# MSS_DTHE register map
Vendor: Texas Instruments
Peripheral module from a debugger description file (folder radar).
Registers are 32-bit, access per field, no defined reset value unless marked. A register's access mark holds for its fields unless they carry their own. Offsets are as the file gives them; lines under a group give offsets from that group; [hi:lo] are bit positions; {n}, {i} and the like mark numbered series; 'fields as' and 'values as' point back to an identical list; <NAME> marks a mode.

## MSS_DTHE
0x00 S_EIP_CONFIG rw
  [31:0] CONFIG — This register is secured request configuration.Writing 3 to this register enables the mreqsecure to enable the write to S_SYSCONFIG register in AES and SHA.
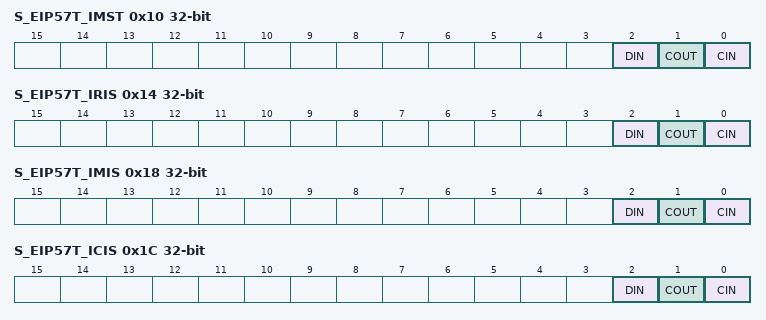
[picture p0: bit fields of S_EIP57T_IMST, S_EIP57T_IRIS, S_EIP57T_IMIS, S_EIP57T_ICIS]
0x10 S_EIP57T_IMST
  [2] DIN rw — Data in: this interrupt is raised when DMA writes last word of input data to internal FIFO of the engine
  [1] COUT rw — Context out: this interrupt is raised when DMA complets the output context movement from internal register
  [0] CIN rw — context in: this interrupt is raised when DMA complets Context write to internal register
0x14 S_EIP57T_IRIS ro
  [2] DIN — input Data movement is done
  [1] COUT — Context output is done
  [0] CIN — context input is done
0x18 S_EIP57T_IMIS ro
  fields as S_EIP57T_IRIS
0x1C S_EIP57T_ICIS
  [2] DIN rw — Clear “input Data movement done” flag
  [1] COUT rw — Clear “Context output done” flag
  [0] CIN rw — Clear “context input done” flag
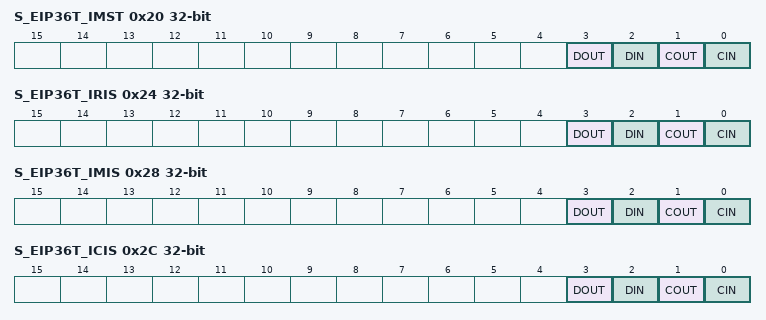
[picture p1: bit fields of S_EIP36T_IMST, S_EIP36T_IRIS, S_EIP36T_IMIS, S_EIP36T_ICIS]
0x20 S_EIP36T_IMST
  [3] DOUT rw — Data out: this interrupt is raised when DMA finishes writing last word of the process result
  [2] DIN rw — Data in: this interrupt is raised when DMA writes last word of input data to internal FIFO of the engine
  [1] COUT rw — Context out: this interrupt is raised when DMA complets the output context movement from internal register
  [0] CIN rw — context in: this interrupt is raised when DMA complets Context write to internal register
0x24 S_EIP36T_IRIS ro
  [3] DOUT — Output Data movement is done
  [2] DIN — input Data movement is done
  [1] COUT — Context output is done
  [0] CIN — context input is done
0x28 S_EIP36T_IMIS ro
  fields as S_EIP36T_IRIS
0x2C S_EIP36T_ICIS
  [3] DOUT rw — Clear “output Data movement done” flag
  [2] DIN rw — Clear “input Data movement done” flag
  [1] COUT rw — Clear “Context output done” flag
  [0] CIN rw — Clear “context input done” flag
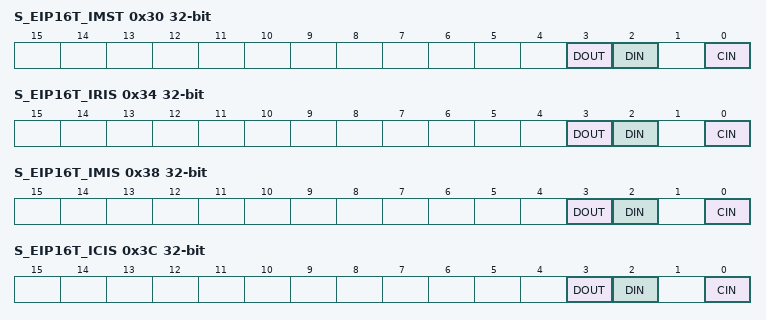
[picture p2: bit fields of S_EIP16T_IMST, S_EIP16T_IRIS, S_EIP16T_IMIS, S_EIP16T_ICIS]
0x30 S_EIP16T_IMST
  [3] DOUT rw — Data out: this interrupt is raised when DMA finishes writing last word of the process result
  [2] DIN rw — Data in: this interrupt is raised when DMA writes last word of input data to internal FIFO of the engine
  [0] CIN rw — context in: this interrupt is raised when DMA complets Context write to internal register
0x34 S_EIP16T_IRIS ro
  [3] DOUT — Output Data movement is done
  [2] DIN — input Data movement is done
  [0] CIN — context input is done
0x38 S_EIP16T_IMIS ro
  fields as S_EIP16T_IRIS
0x3C S_EIP16T_ICIS
  [3] DOUT rw — Clear “output Data movement done” flag
  [2] DIN rw — Clear “input Data movement done” flag
  [0] CIN rw — Clear "context input done” flag
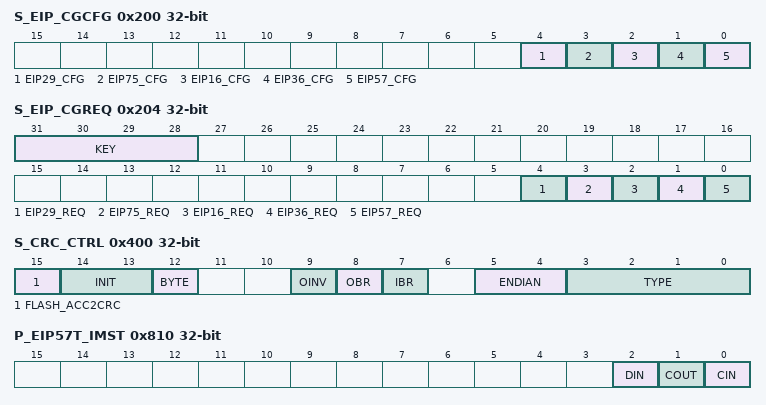
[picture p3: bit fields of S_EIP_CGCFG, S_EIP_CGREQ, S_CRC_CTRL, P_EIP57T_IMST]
0x200 S_EIP_CGCFG
  [4] EIP29_CFG rw — Clock gating protocol setting for EIP29T. 0 – Follow direct protocol 1 – Follow idle_req/ack protocol.
  [3] EIP75_CFG rw — Clock gating protocol setting for EIP75T. 0 – Follow direct protocol 1 – Follow idle_req/ack protocol.
  [2] EIP16_CFG rw — Clock gating protocol setting for EIP16T. 0 – Follow direct protocol 1 – Follow idle_req/ack protocol.
  [1] EIP36_CFG rw — Clock gating protocol setting for EIP36T. 0 – Follow direct protocol 1 – Follow idle_req/ack protocol.
  [0] EIP57_CFG rw — Clock gating protocol setting for EIP57T. 0 – Follow direct protocol 1 – Follow idle_req/ack protocol.
0x204 S_EIP_CGREQ
  [31:28] KEY rw — When “0x5” write “1” to lower bits [4:0] will set the bit. Write “0” will be ignored When “0x2” write “1” to lower bit [4:0] will clear the bit. Write “0” will be ignored for other key value, regular read write operation
  [4] EIP29_REQ rw — 0 – request clock gating 1 – request to un-gate the clock.
  [3] EIP75_REQ rw — 0 – request clock gating 1 – request to un-gate the clock.
  [2] EIP16_REQ rw — 0 – request clock gating 1 – request to un-gate the clock.
  [1] EIP36_REQ rw — 0 – request clock gating 1 – request to un-gate the clock.
  [0] EIP57_REQ rw — 0 – request clock gating 1 – request to un-gate the clock.
0x400 S_CRC_CTRL
  [15] FLASH_ACC2CRC rw — 1 if use Flash access port to feed CRC (uses length and address in that block to control data (Reserved). Only present in DTHE_S_CRC_CTRL register
  [14:13] INIT rw — Initialize the CRC 00 – use SEED register context as starting value 10 – all “zero” 11 – all “one” This is self clearing. With first write to data register this value clears to zero and remain zero for rest of the operation unless written again
  [12] BYTE rw — Input data size 0 – 32 bit 1 – 8 bit
  [9] OINV rw — Inverse the bits of result before storing to CRC_RSLT_PP0
  [8] OBR rw — Bit reserved the output result byte before storing to CRC_RSLT_PP0. applicable for all bytes in word
  [7] IBR rw — Bit reverse the input byte. For all bytes in word
  [5:4] ENDIAN rw — Endian control [0] – swap byte in half-word [1] – swap half word
  [3:0] TYPE rw — Type of operation 0000 – polynomial 0x8005 0001 – polynomial 0x1021 0010 – polynomial 0x4C11DB7 0011 – polynomial 0x1EDC6F41 1000 – TCP checksum TYPE in DTHE_S_CRC_CTRL & DTHE_S_CRC_CTRL should be exclusive
0x410 S_CRC_SEED rw
  [31:0] SEED — Starting seed of CRC and checksum operation. Please see CTRL register for more detail. This resister also holds the latest result of CRC or checksum operation
0x414 S_CRC_DIN rw
  [31:0] DATA_IN — Input data for CRC or checksum operation
0x418 S_CRC_RSLT_PP ro
  [31:0] RSLT_PP — result data of CRC or checksum operation
0x810 P_EIP57T_IMST
  fields as S_EIP57T_IMST
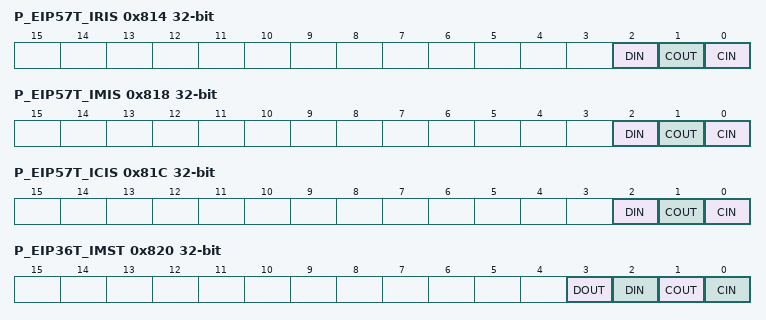
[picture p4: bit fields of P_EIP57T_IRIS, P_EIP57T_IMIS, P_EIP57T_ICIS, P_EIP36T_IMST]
0x814 P_EIP57T_IRIS ro
  fields as S_EIP57T_IRIS
0x818 P_EIP57T_IMIS ro
  fields as S_EIP57T_IRIS
0x81C P_EIP57T_ICIS
  fields as S_EIP57T_ICIS
0x820 P_EIP36T_IMST
  fields as S_EIP36T_IMST
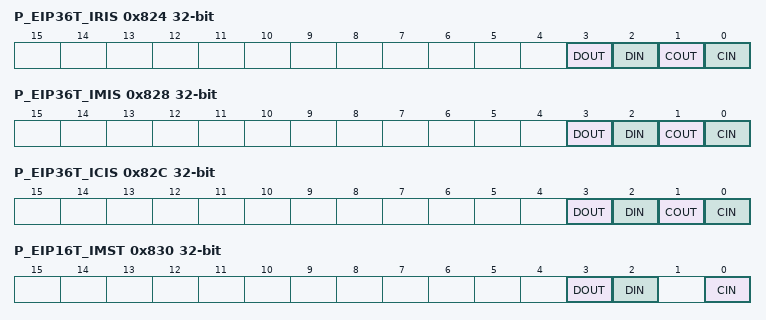
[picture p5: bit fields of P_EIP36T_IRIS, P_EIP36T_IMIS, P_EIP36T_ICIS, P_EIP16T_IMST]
0x824 P_EIP36T_IRIS ro
  fields as S_EIP36T_IRIS
0x828 P_EIP36T_IMIS ro
  fields as S_EIP36T_IRIS
0x82C P_EIP36T_ICIS
  fields as S_EIP36T_ICIS
0x830 P_EIP16T_IMST
  fields as S_EIP16T_IMST
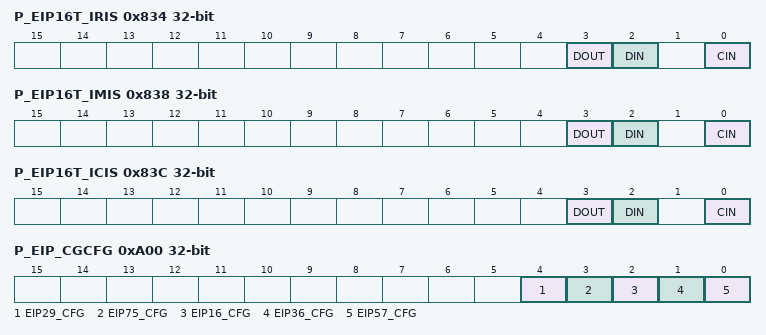
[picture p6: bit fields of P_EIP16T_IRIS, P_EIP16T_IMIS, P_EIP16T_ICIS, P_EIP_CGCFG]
0x834 P_EIP16T_IRIS ro
  fields as S_EIP16T_IRIS
0x838 P_EIP16T_IMIS ro
  fields as S_EIP16T_IRIS
0x83C P_EIP16T_ICIS
  fields as S_EIP16T_ICIS
0xA00 P_EIP_CGCFG
  fields as S_EIP_CGCFG
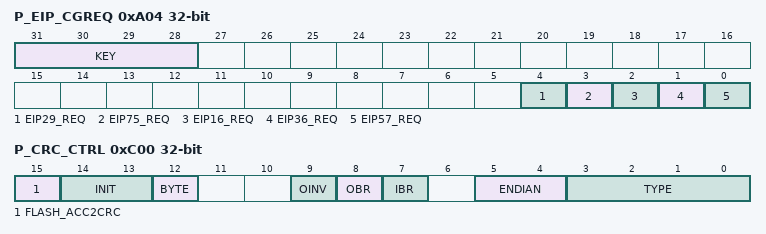
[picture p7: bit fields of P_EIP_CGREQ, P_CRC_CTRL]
0xA04 P_EIP_CGREQ
  fields as S_EIP_CGREQ
0xC00 P_CRC_CTRL
  fields as S_CRC_CTRL
0xC10 P_CRC_SEED rw
  fields as S_CRC_SEED
0xC14 P_CRC_DIN rw
  [31:0] DATA_IN — Input data for CRC or checksum operation
0xC18 P_CRC_RSLT_PP ro
  [31:0] RSLT_PP — result data of CRC or checksum operation
{0xF00+4i} P_RAND_KEY{i} ro (i=0..3)
  [31:0] KEY{32i+31}_{32i} — Device Specific Randon key [{32i+31}:{32i}]
